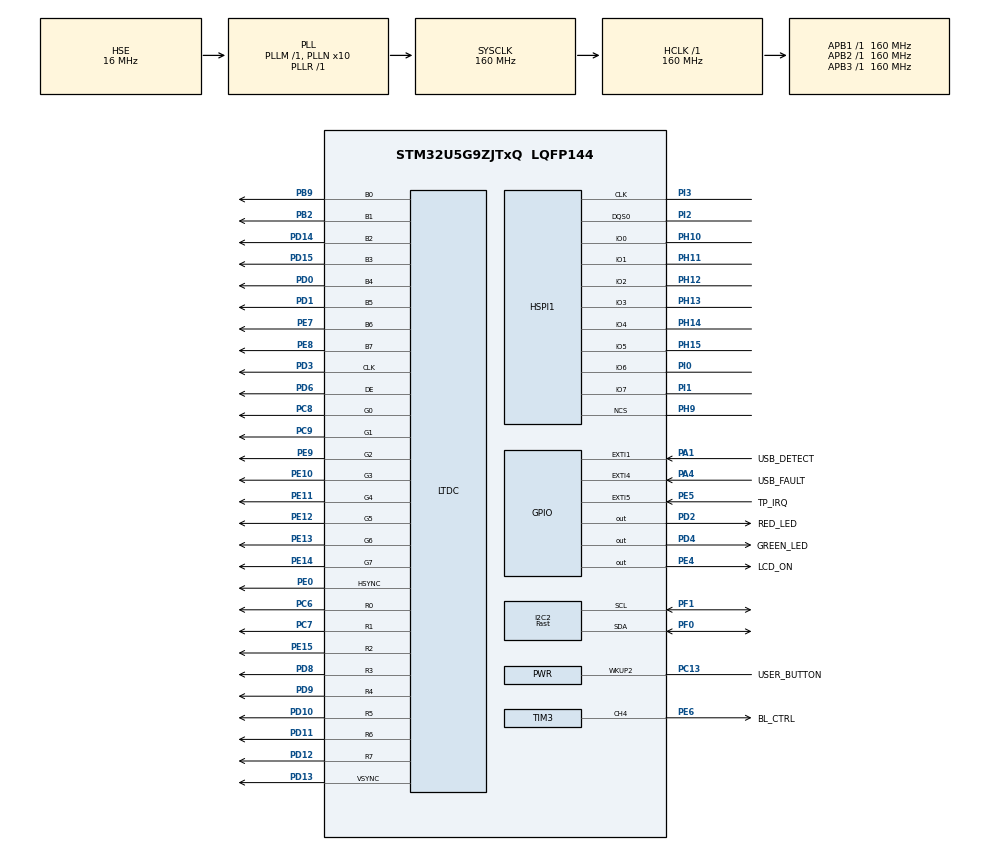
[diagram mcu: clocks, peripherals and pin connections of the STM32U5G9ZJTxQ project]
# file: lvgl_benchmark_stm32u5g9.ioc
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CORTEX_M33_NS.userName=CORTEX_M33
DMA2D.ColorMode=DMA2D_OUTPUT_RGB565
DMA2D.Mode=DMA2D_M2M
GPDMA1.RECAP_GPDMACH0=GPDMA1_REQUEST_JPEG_RX
GPDMA1.RECAP_GPDMACH1=GPDMA1_REQUEST_JPEG_TX
HSPI1.ChipSelectBoundary=HAL_XSPI_BONDARYOF_NONE
HSPI1.ChipSelectHighTimeCycle=2
HSPI1.FifoThresholdByte=4
HSPI1.MemorySize=HAL_XSPI_SIZE_1GB
HSPI1.MemoryType=HAL_XSPI_MEMTYPE_MACRONIX
I2C2.I2C_Speed_Mode=I2C_Fast
I2C2.Timing=0x00F07BFF
JPEG.JPEG_RGB_FORMAT=JPEG_RGB888
LTDC.ActiveH=480
LTDC.ActiveW=800
LTDC.Alpha_L0=255
LTDC.BlendingFactor1_L0=LTDC_BLENDING_FACTOR1_CA
LTDC.BlendingFactor2_L0=LTDC_BLENDING_FACTOR2_CA
LTDC.DEPolarity=LTDC_DEPOLARITY_AL
LTDC.FBStartAdress_L0=0x20000000
LTDC.HBP=8
LTDC.HFP=8
LTDC.HSync=5
LTDC.ImageHeight_L0=480
LTDC.ImageWidth_L0=800
LTDC.Layers=0
LTDC.PCPolarity=LTDC_PCPOLARITY_IPC
LTDC.PixelFormat_L0=LTDC_PIXEL_FORMAT_RGB565
LTDC.VBP=8
LTDC.VFP=14
LTDC.VSync=5
LTDC.WindowX1_L0=800
LTDC.WindowY1_L0=480
Mcu.Family=STM32U5
Mcu.Name=STM32U5G9ZJTxQ
Mcu.Package=LQFP144
NVIC.DMA2D_IRQn=true\:0\:0\:false\:false\:true\:true\:true\:true
NVIC.EXTI1_IRQn=true\:0\:0\:false\:false\:true\:true\:true\:true
NVIC.EXTI4_IRQn=true\:0\:0\:false\:false\:true\:true\:true\:true
NVIC.EXTI5_IRQn=true\:0\:0\:false\:false\:true\:true\:true\:true
NVIC.GPU2D_IRQn=true\:0\:0\:false\:false\:true\:true\:true\:true
NVIC.LTDC_IRQn=true\:0\:0\:false\:false\:true\:true\:true\:true
NVIC.PriorityGroup=NVIC_PRIORITYGROUP_4
PA1.GPIO_Label=USB_DETECT
PA1.GPIO_ModeDefaultEXTI=GPIO_MODE_IT_RISING_FALLING
PA1.Signal=GPXTI1
PA10.Signal=USART1_RX
PA11.Signal=USB_OTG_HS_DM
PA12.Signal=USB_OTG_HS_DP
PA13\ (JTMS/SWDIO).Mode=Trace_Asynchronous_SW
PA13\ (JTMS/SWDIO).Signal=DEBUG_JTMS-SWDIO
PA14\ (JTCK/SWCLK).Mode=Trace_Asynchronous_SW
PA14\ (JTCK/SWCLK).Signal=DEBUG_JTCK-SWCLK
PA4.GPIO_Label=USB_FAULT
PA4.GPIO_ModeDefaultEXTI=GPIO_MODE_IT_FALLING
PA4.GPIO_PuPd=GPIO_PULLUP
PA4.Signal=GPXTI4
PA9.Signal=USART1_TX
PB2.GPIO_Speed=GPIO_SPEED_FREQ_VERY_HIGH
PB2.Mode=RGB888
PB2.Signal=LTDC_B1
PB3\ (JTDO/TRACESWO).Mode=Trace_Asynchronous_SW
PB3\ (JTDO/TRACESWO).Signal=DEBUG_JTDO-SWO
PB9.GPIO_Speed=GPIO_SPEED_FREQ_VERY_HIGH
PB9.Mode=RGB888
PB9.Signal=LTDC_B0
PC13.GPIO_Label=USER_BUTTON
PC13.Mode=WakeUp2
PC13.Signal=PWR_WKUP2
PC14-OSC32_IN\ (PC14).Mode=LSE-External-Oscillator
PC14-OSC32_IN\ (PC14).Signal=RCC_OSC32_IN
PC15-OSC32_OUT\ (PC15).Mode=LSE-External-Oscillator
PC15-OSC32_OUT\ (PC15).Signal=RCC_OSC32_OUT
PC6.GPIO_Speed=GPIO_SPEED_FREQ_VERY_HIGH
PC6.Mode=RGB888
PC6.Signal=LTDC_R0
PC7.GPIO_Speed=GPIO_SPEED_FREQ_VERY_HIGH
PC7.Mode=RGB888
PC7.Signal=LTDC_R1
PC8.GPIO_Speed=GPIO_SPEED_FREQ_VERY_HIGH
PC8.Mode=RGB888
PC8.Signal=LTDC_G0
PC9.GPIO_Speed=GPIO_SPEED_FREQ_VERY_HIGH
PC9.Mode=RGB888
PC9.Signal=LTDC_G1
PD0.GPIO_Speed=GPIO_SPEED_FREQ_VERY_HIGH
PD0.Mode=RGB888
PD0.Signal=LTDC_B4
PD1.GPIO_Speed=GPIO_SPEED_FREQ_VERY_HIGH
PD1.Mode=RGB888
PD1.Signal=LTDC_B5
PD10.GPIO_Speed=GPIO_SPEED_FREQ_VERY_HIGH
PD10.Mode=RGB888
PD10.Signal=LTDC_R5
PD11.GPIO_Speed=GPIO_SPEED_FREQ_VERY_HIGH
PD11.Mode=RGB888
PD11.Signal=LTDC_R6
PD12.GPIO_Speed=GPIO_SPEED_FREQ_VERY_HIGH
PD12.Mode=RGB888
PD12.Signal=LTDC_R7
PD13.GPIO_Speed=GPIO_SPEED_FREQ_VERY_HIGH
PD13.Mode=RGB888
PD13.Signal=LTDC_VSYNC
PD14.GPIO_Speed=GPIO_SPEED_FREQ_VERY_HIGH
PD14.Mode=RGB888
PD14.Signal=LTDC_B2
PD15.GPIO_Speed=GPIO_SPEED_FREQ_VERY_HIGH
PD15.Mode=RGB888
PD15.Signal=LTDC_B3
PD2.GPIO_Label=RED_LED
PD2.Signal=GPIO_Output
PD3.GPIO_Speed=GPIO_SPEED_FREQ_VERY_HIGH
PD3.Mode=RGB888
PD3.Signal=LTDC_CLK
PD4.GPIO_Label=GREEN_LED
PD4.Signal=GPIO_Output
PD6.GPIO_Speed=GPIO_SPEED_FREQ_VERY_HIGH
PD6.Mode=RGB888
PD6.Signal=LTDC_DE
PD8.GPIO_Speed=GPIO_SPEED_FREQ_VERY_HIGH
PD8.Mode=RGB888
PD8.Signal=LTDC_R3
PD9.GPIO_Speed=GPIO_SPEED_FREQ_VERY_HIGH
PD9.Mode=RGB888
PD9.Signal=LTDC_R4
PE0.GPIO_Speed=GPIO_SPEED_FREQ_VERY_HIGH
PE0.Mode=RGB888
PE0.Signal=LTDC_HSYNC
PE10.GPIO_Speed=GPIO_SPEED_FREQ_VERY_HIGH
PE10.Mode=RGB888
PE10.Signal=LTDC_G3
PE11.GPIO_Speed=GPIO_SPEED_FREQ_VERY_HIGH
PE11.Mode=RGB888
PE11.Signal=LTDC_G4
PE12.GPIO_Speed=GPIO_SPEED_FREQ_VERY_HIGH
PE12.Mode=RGB888
PE12.Signal=LTDC_G5
PE13.GPIO_Speed=GPIO_SPEED_FREQ_VERY_HIGH
PE13.Mode=RGB888
PE13.Signal=LTDC_G6
PE14.GPIO_Speed=GPIO_SPEED_FREQ_VERY_HIGH
PE14.Mode=RGB888
PE14.Signal=LTDC_G7
PE15.GPIO_Speed=GPIO_SPEED_FREQ_VERY_HIGH
PE15.Mode=RGB888
PE15.Signal=LTDC_R2
PE4.GPIO_Label=LCD_ON
PE4.PinState=GPIO_PIN_SET
PE4.Signal=GPIO_Output
PE5.GPIO_Label=TP_IRQ
PE5.GPIO_ModeDefaultEXTI=GPIO_MODE_IT_FALLING
PE5.GPIO_PuPd=GPIO_PULLUP
PE5.Signal=GPXTI5
PE6.GPIO_Label=BL_CTRL
PE6.Signal=S_TIM3_CH4
PE7.GPIO_Speed=GPIO_SPEED_FREQ_VERY_HIGH
PE7.Mode=RGB888
PE7.Signal=LTDC_B6
PE8.GPIO_Speed=GPIO_SPEED_FREQ_VERY_HIGH
PE8.Mode=RGB888
PE8.Signal=LTDC_B7
PE9.GPIO_Speed=GPIO_SPEED_FREQ_VERY_HIGH
PE9.Mode=RGB888
PE9.Signal=LTDC_G2
PF0.Mode=I2C
PF0.Signal=I2C2_SDA
PF1.Mode=I2C
PF1.Signal=I2C2_SCL
PH0-OSC_IN\ (PH0).Mode=HSE-External-Oscillator
PH0-OSC_IN\ (PH0).Signal=RCC_OSC_IN
PH1-OSC_OUT\ (PH1).Mode=HSE-External-Oscillator
PH1-OSC_OUT\ (PH1).Signal=RCC_OSC_OUT
PH10.Mode=octo_mode
PH10.Signal=HSPI1_IO0
PH11.Mode=octo_mode
PH11.Signal=HSPI1_IO1
PH12.Mode=octo_mode
PH12.Signal=HSPI1_IO2
PH13.Mode=octo_mode
PH13.Signal=HSPI1_IO3
PH14.Mode=octo_mode
PH14.Signal=HSPI1_IO4
PH15.Mode=octo_mode
PH15.Signal=HSPI1_IO5
PH9.Mode=octo_mode
PH9.Signal=HSPI1_NCS
PI0.Mode=octo_mode
PI0.Signal=HSPI1_IO6
PI1.Mode=octo_mode
PI1.Signal=HSPI1_IO7
PI2.Mode=octo_mode
PI2.Signal=HSPI1_DQS0
PI3.Mode=octo_mode
PI3.Signal=HSPI1_CLK
PWR.PowerMode=PWR_SMPS_SUPPLY
ProjectManager.HeapSize=0x200
ProjectManager.StackSize=0x400
ProjectManager.TargetToolchain=STM32CubeIDE
RCC.ADCFreq_Value=16000000
RCC.AHBFreq_Value=160000000
RCC.APB1Freq_Value=160000000
RCC.APB1TimFreq_Value=160000000
RCC.APB2Freq_Value=160000000
RCC.APB2TimFreq_Value=160000000
RCC.APB3Freq_Value=160000000
RCC.CortexFreq_Value=160000000
RCC.EPOD_VALUE=16000000
RCC.HCLKFreq_Value=160000000
RCC.HSE_VALUE=16000000
RCC.HSI48_VALUE=48000000
RCC.HSI_VALUE=16000000
RCC.HSPICLockSelection=RCC_HSPICLKSOURCE_PLL2
RCC.LSIDIV_VALUE=32000
RCC.LTDCCLockSelection=RCC_LTDCCLKSOURCE_PLL3
RCC.MSIClockRange=RCC_MSIRANGE_0
RCC.MSI_VALUE=48000000
RCC.PLL1P=8
RCC.PLL1R=1
RCC.PLL2FRACN=0
RCC.PLL2N=25
RCC.PLL2Q=3
RCC.PLL2R=4
RCC.PLL2Source=RCC_PLLSOURCE_HSE
RCC.PLL3FRACN=0
RCC.PLL3M=4
RCC.PLL3N=50
RCC.PLL3R=8
RCC.PLL3Source=RCC_PLLSOURCE_HSE
RCC.PLLFRACN=0
RCC.PLLN=10
RCC.PLLSourceVirtual=RCC_PLLSOURCE_HSE
RCC.RTCClockSelection=RCC_RTCCLKSOURCE_LSE
RCC.SYSCLKFreq_VALUE=160000000
RCC.SYSCLKSource=RCC_SYSCLKSOURCE_PLLCLK
RCC.VCOOutputFreq_Value=160000000
SH.S_TIM3_CH4.0=TIM3_CH4,PWM Generation4 CH4
STMicroelectronics.X-CUBE-FREERTOS.1.3.1.configENABLE_FPU=1
STMicroelectronics.X-CUBE-FREERTOS.1.3.1.configENABLE_MVE=0
STMicroelectronics.X-CUBE-FREERTOS.1.3.1.configMINIMAL_STACK_SIZE=4096
STMicroelectronics.X-CUBE-FREERTOS.1.3.1.configTOTAL_HEAP_SIZE=1024*256
STMicroelectronics.X-CUBE-FREERTOS.1.3.1.configUSE_TICK_HOOK=1
TIM3.Channel-PWM\ Generation4\ CH4=TIM_CHANNEL_4
TIM3.OC4Preload_PWM=DISABLE
TIM3.PeriodNoDither=100
TIM3.Prescaler=160
TIM3.PulseNoDither_4=75
VP_DCACHE1_VS_DCACHE.Mode=DCACHE_Activate
VP_DCACHE2_VS_DCACHE.Mode=DCACHE_Activate
VP_DMA2D_VS_DMA2D.Mode=DMA2D_Activate
VP_GPDMA1_VS_GPDMACH0.Mode=SIMPLEREQUEST_GPDMACH0
VP_GPDMA1_VS_GPDMACH1.Mode=SIMPLEREQUEST_GPDMACH1
VP_GPU2D_VS_GPU2D.Mode=GPU2D_Activate
VP_ICACHE_VS_ICACHE.Mode=DirectMappedCache
VP_JPEG_VS_JPEG.Mode=JPEG_Activate
VP_LPBAMQUEUE_VS_QUEUE.Mode=QUEUEMODE
VP_LPBAM_VS_SIG1.Mode=SmartRun
VP_LPBAM_VS_SIG4.Mode=LPDMA1
VP_MEMORYMAP_VS_MEMORYMAP.Mode=CurAppReg
VP_PWR_VS_LPOM.Mode=PowerOptimisation
VP_PWR_VS_SECSignals.Mode=Security/Privilege
board=STM32U5G9J-DK2

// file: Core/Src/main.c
/* USER CODE BEGIN Header */
/**
  ******************************************************************************
  * @file           : main.c
  * @brief          : Main program body
  ******************************************************************************
  * @attention
  *
  * Copyright (c) 2026 STMicroelectronics.
  * All rights reserved.
  *
  * This software is licensed under terms that can be found in the LICENSE file
  * in the root directory of this software component.
  * If no LICENSE file comes with this software, it is provided AS-IS.
  *
  ******************************************************************************
  */
/* USER CODE END Header */
#include "main.h"
#include "jpeg_utils_conf.h"

/* USER CODE BEGIN Includes */
#include "lvgl_port_display.h"
#include "lvgl.h"
//#include "../lvgl/examples/lv_examples.h"
#include "examples/lv_examples.h"
#include "demos/lv_demos.h"
//#include "app_freertos.h"
/* USER CODE END Includes */

DCACHE_HandleTypeDef hdcache1;
DCACHE_HandleTypeDef hdcache2;

DMA2D_HandleTypeDef hdma2d;

DMA_HandleTypeDef handle_GPDMA1_Channel1;
DMA_HandleTypeDef handle_GPDMA1_Channel0;

GPU2D_HandleTypeDef hgpu2d;

XSPI_HandleTypeDef hxspi1;

I2C_HandleTypeDef hi2c2;

JPEG_HandleTypeDef hjpeg;

LTDC_HandleTypeDef hltdc;

TIM_HandleTypeDef htim3;

/* USER CODE BEGIN PV */

//volatile __attribute__((aligned(16))) uint8_t ltdc_framebuffer[800 * 480 * 2]; //FIXME A remettre si on veut que ca fonctionne
/* USER CODE END PV */

void SystemClock_Config(void);
static void SystemPower_Config(void);
static void MX_GPIO_Init(void);
static void MX_GPDMA1_Init(void);
static void MX_DMA2D_Init(void);
static void MX_HSPI1_Init(void);
static void MX_I2C2_Init(void);
static void MX_ICACHE_Init(void);
static void MX_LTDC_Init(void);
static void MX_TIM3_Init(void);
static void MX_JPEG_Init(void);
static void MX_DCACHE1_Init(void);
static void MX_GPU2D_Init(void);
static void MX_DCACHE2_Init(void);

int main(void)
{

  /* MCU Configuration--------------------------------------------------------*/

  /* Reset of all peripherals, Initializes the Flash interface and the Systick. */
  HAL_Init();

  /* Configure the System Power */
  SystemPower_Config();

  /* Configure the system clock */
  SystemClock_Config();

  /* Initialize all configured peripherals */
  MX_GPIO_Init();
  MX_GPDMA1_Init();
  MX_DMA2D_Init();
  MX_HSPI1_Init();
  MX_I2C2_Init();
  MX_ICACHE_Init();
  MX_LTDC_Init();
  MX_TIM3_Init();
  MX_JPEG_Init();
  MX_DCACHE1_Init();
  MX_GPU2D_Init();
  MX_DCACHE2_Init();
  /* USER CODE BEGIN 2 */
lv_init();
lvgl_display_init ();
//lv_demo_music();
//lv_demo_benchmark();
//lv_example_svg_1();
lv_example_label_1();
  /* USER CODE END 2 */

  /* Infinite loop */
  /* USER CODE BEGIN WHILE */
  while (1)
  {
	    lv_timer_handler();
	    HAL_Delay(1);
    /* USER CODE END WHILE */

  }
}

void SystemClock_Config(void)
{
  RCC_OscInitTypeDef RCC_OscInitStruct = {0};
  RCC_ClkInitTypeDef RCC_ClkInitStruct = {0};

  /** Configure the main internal regulator output voltage
  */
  if (HAL_PWREx_ControlVoltageScaling(PWR_REGULATOR_VOLTAGE_SCALE1) != HAL_OK)
  {
    Error_Handler();
  }

  /** Initializes the CPU, AHB and APB buses clocks
  */
  RCC_OscInitStruct.OscillatorType = RCC_OSCILLATORTYPE_HSE;
  RCC_OscInitStruct.HSEState = RCC_HSE_ON;
  RCC_OscInitStruct.PLL.PLLState = RCC_PLL_ON;
  RCC_OscInitStruct.PLL.PLLSource = RCC_PLLSOURCE_HSE;
  RCC_OscInitStruct.PLL.PLLMBOOST = RCC_PLLMBOOST_DIV1;
  RCC_OscInitStruct.PLL.PLLM = 1;
  RCC_OscInitStruct.PLL.PLLN = 10;
  RCC_OscInitStruct.PLL.PLLP = 8;
  RCC_OscInitStruct.PLL.PLLQ = 2;
  RCC_OscInitStruct.PLL.PLLR = 1;
  RCC_OscInitStruct.PLL.PLLRGE = RCC_PLLVCIRANGE_1;
  RCC_OscInitStruct.PLL.PLLFRACN = 0;
  if (HAL_RCC_OscConfig(&RCC_OscInitStruct) != HAL_OK)
  {
    Error_Handler();
  }

  /** Initializes the CPU, AHB and APB buses clocks
  */
  RCC_ClkInitStruct.ClockType = RCC_CLOCKTYPE_HCLK|RCC_CLOCKTYPE_SYSCLK
                              |RCC_CLOCKTYPE_PCLK1|RCC_CLOCKTYPE_PCLK2
                              |RCC_CLOCKTYPE_PCLK3;
  RCC_ClkInitStruct.SYSCLKSource = RCC_SYSCLKSOURCE_PLLCLK;
  RCC_ClkInitStruct.AHBCLKDivider = RCC_SYSCLK_DIV1;
  RCC_ClkInitStruct.APB1CLKDivider = RCC_HCLK_DIV1;
  RCC_ClkInitStruct.APB2CLKDivider = RCC_HCLK_DIV1;
  RCC_ClkInitStruct.APB3CLKDivider = RCC_HCLK_DIV1;

  if (HAL_RCC_ClockConfig(&RCC_ClkInitStruct, FLASH_LATENCY_4) != HAL_OK)
  {
    Error_Handler();
  }
}

/**
  * @brief Power Configuration
  * @retval None
  */
static void SystemPower_Config(void)
{

  /*
   * Switch to SMPS regulator instead of LDO
   */
  if (HAL_PWREx_ConfigSupply(PWR_SMPS_SUPPLY) != HAL_OK)
  {
    Error_Handler();
  }
}

static void MX_DCACHE1_Init(void)
{

  hdcache1.Instance = DCACHE1;
  hdcache1.Init.ReadBurstType = DCACHE_READ_BURST_WRAP;
  if (HAL_DCACHE_Init(&hdcache1) != HAL_OK)
  {
    Error_Handler();
  }

}

static void MX_DCACHE2_Init(void)
{

  hdcache2.Instance = DCACHE2;
  hdcache2.Init.ReadBurstType = DCACHE_READ_BURST_WRAP;
  if (HAL_DCACHE_Init(&hdcache2) != HAL_OK)
  {
    Error_Handler();
  }
   __HAL_RCC_SYSCFG_CLK_ENABLE();
   HAL_SYSCFG_DisableSRAMCached();

}

static void MX_DMA2D_Init(void)
{

  hdma2d.Instance = DMA2D;
  hdma2d.Init.Mode = DMA2D_M2M;
  hdma2d.Init.ColorMode = DMA2D_OUTPUT_RGB565;
  hdma2d.Init.OutputOffset = 0;
  hdma2d.Init.BytesSwap = DMA2D_BYTES_REGULAR;
  hdma2d.Init.LineOffsetMode = DMA2D_LOM_PIXELS;
  hdma2d.LayerCfg[1].InputOffset = 0;
  hdma2d.LayerCfg[1].InputColorMode = DMA2D_INPUT_RGB565;
  hdma2d.LayerCfg[1].AlphaMode = DMA2D_NO_MODIF_ALPHA;
  hdma2d.LayerCfg[1].InputAlpha = 0;
  hdma2d.LayerCfg[1].AlphaInverted = DMA2D_REGULAR_ALPHA;
  hdma2d.LayerCfg[1].RedBlueSwap = DMA2D_RB_REGULAR;
  if (HAL_DMA2D_Init(&hdma2d) != HAL_OK)
  {
    Error_Handler();
  }
  if (HAL_DMA2D_ConfigLayer(&hdma2d, 1) != HAL_OK)
  {
    Error_Handler();
  }

}

static void MX_GPDMA1_Init(void)
{

  /* Peripheral clock enable */
  __HAL_RCC_GPDMA1_CLK_ENABLE();

  handle_GPDMA1_Channel1.Instance = GPDMA1_Channel1;
  handle_GPDMA1_Channel1.Init.Request = DMA_REQUEST_SW;
  handle_GPDMA1_Channel1.Init.BlkHWRequest = DMA_BREQ_SINGLE_BURST;
  handle_GPDMA1_Channel1.Init.Direction = DMA_MEMORY_TO_MEMORY;
  handle_GPDMA1_Channel1.Init.SrcInc = DMA_SINC_FIXED;
  handle_GPDMA1_Channel1.Init.DestInc = DMA_DINC_FIXED;
  handle_GPDMA1_Channel1.Init.SrcDataWidth = DMA_SRC_DATAWIDTH_BYTE;
  handle_GPDMA1_Channel1.Init.DestDataWidth = DMA_DEST_DATAWIDTH_BYTE;
  handle_GPDMA1_Channel1.Init.Priority = DMA_LOW_PRIORITY_LOW_WEIGHT;
  handle_GPDMA1_Channel1.Init.SrcBurstLength = 1;
  handle_GPDMA1_Channel1.Init.DestBurstLength = 1;
  handle_GPDMA1_Channel1.Init.TransferAllocatedPort = DMA_SRC_ALLOCATED_PORT0|DMA_DEST_ALLOCATED_PORT0;
  handle_GPDMA1_Channel1.Init.TransferEventMode = DMA_TCEM_BLOCK_TRANSFER;
  handle_GPDMA1_Channel1.Init.Mode = DMA_NORMAL;
  if (HAL_DMA_Init(&handle_GPDMA1_Channel1) != HAL_OK)
  {
    Error_Handler();
  }
  if (HAL_DMA_ConfigChannelAttributes(&handle_GPDMA1_Channel1, DMA_CHANNEL_NPRIV) != HAL_OK)
  {
    Error_Handler();
  }
  handle_GPDMA1_Channel0.Instance = GPDMA1_Channel0;
  handle_GPDMA1_Channel0.Init.Request = DMA_REQUEST_SW;
  handle_GPDMA1_Channel0.Init.BlkHWRequest = DMA_BREQ_SINGLE_BURST;
  handle_GPDMA1_Channel0.Init.Direction = DMA_MEMORY_TO_MEMORY;
  handle_GPDMA1_Channel0.Init.SrcInc = DMA_SINC_FIXED;
  handle_GPDMA1_Channel0.Init.DestInc = DMA_DINC_FIXED;
  handle_GPDMA1_Channel0.Init.SrcDataWidth = DMA_SRC_DATAWIDTH_BYTE;
  handle_GPDMA1_Channel0.Init.DestDataWidth = DMA_DEST_DATAWIDTH_BYTE;
  handle_GPDMA1_Channel0.Init.Priority = DMA_LOW_PRIORITY_LOW_WEIGHT;
  handle_GPDMA1_Channel0.Init.SrcBurstLength = 1;
  handle_GPDMA1_Channel0.Init.DestBurstLength = 1;
  handle_GPDMA1_Channel0.Init.TransferAllocatedPort = DMA_SRC_ALLOCATED_PORT0|DMA_DEST_ALLOCATED_PORT0;
  handle_GPDMA1_Channel0.Init.TransferEventMode = DMA_TCEM_BLOCK_TRANSFER;
  handle_GPDMA1_Channel0.Init.Mode = DMA_NORMAL;
  if (HAL_DMA_Init(&handle_GPDMA1_Channel0) != HAL_OK)
  {
    Error_Handler();
  }
  if (HAL_DMA_ConfigChannelAttributes(&handle_GPDMA1_Channel0, DMA_CHANNEL_NPRIV) != HAL_OK)
  {
    Error_Handler();
  }

}

static void MX_GPU2D_Init(void)
{

  hgpu2d.Instance = GPU2D;
  if (HAL_GPU2D_Init(&hgpu2d) != HAL_OK)
  {
    Error_Handler();
  }

}

static void MX_HSPI1_Init(void)
{

  /* HSPI1 parameter configuration*/
  hxspi1.Instance = HSPI1;
  hxspi1.Init.FifoThresholdByte = 4;
  hxspi1.Init.MemoryMode = HAL_XSPI_SINGLE_MEM;
  hxspi1.Init.MemoryType = HAL_XSPI_MEMTYPE_MACRONIX;
  hxspi1.Init.MemorySize = HAL_XSPI_SIZE_1GB;
  hxspi1.Init.ChipSelectHighTimeCycle = 2;
  hxspi1.Init.FreeRunningClock = HAL_XSPI_FREERUNCLK_DISABLE;
  hxspi1.Init.ClockMode = HAL_XSPI_CLOCK_MODE_0;
  hxspi1.Init.WrapSize = HAL_XSPI_WRAP_NOT_SUPPORTED;
  hxspi1.Init.ClockPrescaler = 0;
  hxspi1.Init.SampleShifting = HAL_XSPI_SAMPLE_SHIFT_NONE;
  hxspi1.Init.DelayHoldQuarterCycle = HAL_XSPI_DHQC_DISABLE;
  hxspi1.Init.ChipSelectBoundary = HAL_XSPI_BONDARYOF_NONE;
  hxspi1.Init.MaxTran = 0;
  hxspi1.Init.Refresh = 0;
  if (HAL_XSPI_Init(&hxspi1) != HAL_OK)
  {
    Error_Handler();
  }

}

static void MX_I2C2_Init(void)
{

  hi2c2.Instance = I2C2;
  hi2c2.Init.Timing = 0x00F07BFF;
  hi2c2.Init.OwnAddress1 = 0;
  hi2c2.Init.AddressingMode = I2C_ADDRESSINGMODE_7BIT;
  hi2c2.Init.DualAddressMode = I2C_DUALADDRESS_DISABLE;
  hi2c2.Init.OwnAddress2 = 0;
  hi2c2.Init.OwnAddress2Masks = I2C_OA2_NOMASK;
  hi2c2.Init.GeneralCallMode = I2C_GENERALCALL_DISABLE;
  hi2c2.Init.NoStretchMode = I2C_NOSTRETCH_DISABLE;
  if (HAL_I2C_Init(&hi2c2) != HAL_OK)
  {
    Error_Handler();
  }

  /** Configure Analogue filter
  */
  if (HAL_I2CEx_ConfigAnalogFilter(&hi2c2, I2C_ANALOGFILTER_ENABLE) != HAL_OK)
  {
    Error_Handler();
  }

  /** Configure Digital filter
  */
  if (HAL_I2CEx_ConfigDigitalFilter(&hi2c2, 0) != HAL_OK)
  {
    Error_Handler();
  }

}

static void MX_ICACHE_Init(void)
{

  /** Enable instruction cache in 1-way (direct mapped cache)
  */
  if (HAL_ICACHE_ConfigAssociativityMode(ICACHE_1WAY) != HAL_OK)
  {
    Error_Handler();
  }
  if (HAL_ICACHE_Enable() != HAL_OK)
  {
    Error_Handler();
  }

}

static void MX_JPEG_Init(void)
{

  hjpeg.Instance = JPEG;
  if (HAL_JPEG_Init(&hjpeg) != HAL_OK)
  {
    Error_Handler();
  }

}

static void MX_LTDC_Init(void)
{

  LTDC_LayerCfgTypeDef pLayerCfg = {0};

  hltdc.Instance = LTDC;
  hltdc.Init.HSPolarity = LTDC_HSPOLARITY_AL;
  hltdc.Init.VSPolarity = LTDC_VSPOLARITY_AL;
  hltdc.Init.DEPolarity = LTDC_DEPOLARITY_AL;
  hltdc.Init.PCPolarity = LTDC_PCPOLARITY_IPC;
  hltdc.Init.HorizontalSync = 4;
  hltdc.Init.VerticalSync = 4;
  hltdc.Init.AccumulatedHBP = 12;
  hltdc.Init.AccumulatedVBP = 12;
  hltdc.Init.AccumulatedActiveW = 812;
  hltdc.Init.AccumulatedActiveH = 492;
  hltdc.Init.TotalWidth = 820;
  hltdc.Init.TotalHeigh = 506;
  hltdc.Init.Backcolor.Blue = 0;
  hltdc.Init.Backcolor.Green = 0;
  hltdc.Init.Backcolor.Red = 0;
  if (HAL_LTDC_Init(&hltdc) != HAL_OK)
  {
    Error_Handler();
  }
  pLayerCfg.WindowX0 = 0;
  pLayerCfg.WindowX1 = 800;
  pLayerCfg.WindowY0 = 0;
  pLayerCfg.WindowY1 = 480;
  pLayerCfg.PixelFormat = LTDC_PIXEL_FORMAT_RGB565;
  pLayerCfg.Alpha = 255;
  pLayerCfg.Alpha0 = 0;
  pLayerCfg.BlendingFactor1 = LTDC_BLENDING_FACTOR1_CA;
  pLayerCfg.BlendingFactor2 = LTDC_BLENDING_FACTOR2_CA;
  pLayerCfg.FBStartAdress = 0x20000000;
  pLayerCfg.ImageWidth = 800;
  pLayerCfg.ImageHeight = 480;
  pLayerCfg.Backcolor.Blue = 0;
  pLayerCfg.Backcolor.Green = 0;
  pLayerCfg.Backcolor.Red = 0;
  if (HAL_LTDC_ConfigLayer(&hltdc, &pLayerCfg, 0) != HAL_OK)
  {
    Error_Handler();
  }
  /* USER CODE BEGIN LTDC_Init 2 */
  //FIXME A remettre si on veut que ca fonctionne
//  pLayerCfg.FBStartAdress = (uint32_t)ltdc_framebuffer;
//  if (HAL_LTDC_ConfigLayer(&hltdc, &pLayerCfg, 0) != HAL_OK)
//  {
//    Error_Handler();
//  }
  /* USER CODE END LTDC_Init 2 */

}

static void MX_TIM3_Init(void)
{

  TIM_MasterConfigTypeDef sMasterConfig = {0};
  TIM_OC_InitTypeDef sConfigOC = {0};

  htim3.Instance = TIM3;
  htim3.Init.Prescaler = 160;
  htim3.Init.CounterMode = TIM_COUNTERMODE_UP;
  htim3.Init.Period = 100;
  htim3.Init.ClockDivision = TIM_CLOCKDIVISION_DIV1;
  htim3.Init.AutoReloadPreload = TIM_AUTORELOAD_PRELOAD_DISABLE;
  if (HAL_TIM_PWM_Init(&htim3) != HAL_OK)
  {
    Error_Handler();
  }
  sMasterConfig.MasterOutputTrigger = TIM_TRGO_RESET;
  sMasterConfig.MasterSlaveMode = TIM_MASTERSLAVEMODE_DISABLE;
  if (HAL_TIMEx_MasterConfigSynchronization(&htim3, &sMasterConfig) != HAL_OK)
  {
    Error_Handler();
  }
  sConfigOC.OCMode = TIM_OCMODE_PWM1;
  sConfigOC.Pulse = 75;
  sConfigOC.OCPolarity = TIM_OCPOLARITY_HIGH;
  sConfigOC.OCFastMode = TIM_OCFAST_DISABLE;
  if (HAL_TIM_PWM_ConfigChannel(&htim3, &sConfigOC, TIM_CHANNEL_4) != HAL_OK)
  {
    Error_Handler();
  }
  __HAL_TIM_DISABLE_OCxPRELOAD(&htim3, TIM_CHANNEL_4);
  HAL_TIM_MspPostInit(&htim3);

}

static void MX_GPIO_Init(void)
{
  GPIO_InitTypeDef GPIO_InitStruct = {0};

  /* GPIO Ports Clock Enable */
  __HAL_RCC_GPIOE_CLK_ENABLE();
  __HAL_RCC_GPIOC_CLK_ENABLE();
  __HAL_RCC_GPIOF_CLK_ENABLE();
  __HAL_RCC_GPIOH_CLK_ENABLE();
  __HAL_RCC_GPIOA_CLK_ENABLE();
  __HAL_RCC_GPIOB_CLK_ENABLE();
  __HAL_RCC_GPIOD_CLK_ENABLE();
  __HAL_RCC_GPIOI_CLK_ENABLE();

  /*Configure GPIO pin Output Level */
  HAL_GPIO_WritePin(LCD_ON_GPIO_Port, LCD_ON_Pin, GPIO_PIN_SET);

  /*Configure GPIO pin Output Level */
  HAL_GPIO_WritePin(GPIOD, RED_LED_Pin|GREEN_LED_Pin, GPIO_PIN_RESET);

  /*Configure GPIO pin : LCD_ON_Pin */
  GPIO_InitStruct.Pin = LCD_ON_Pin;
  GPIO_InitStruct.Mode = GPIO_MODE_OUTPUT_PP;
  GPIO_InitStruct.Pull = GPIO_NOPULL;
  GPIO_InitStruct.Speed = GPIO_SPEED_FREQ_LOW;
  HAL_GPIO_Init(LCD_ON_GPIO_Port, &GPIO_InitStruct);

  /*Configure GPIO pin : TP_IRQ_Pin */
  GPIO_InitStruct.Pin = TP_IRQ_Pin;
  GPIO_InitStruct.Mode = GPIO_MODE_IT_FALLING;
  GPIO_InitStruct.Pull = GPIO_PULLUP;
  HAL_GPIO_Init(TP_IRQ_GPIO_Port, &GPIO_InitStruct);

  /*Configure GPIO pin : USB_DETECT_Pin */
  GPIO_InitStruct.Pin = USB_DETECT_Pin;
  GPIO_InitStruct.Mode = GPIO_MODE_IT_RISING_FALLING;
  GPIO_InitStruct.Pull = GPIO_NOPULL;
  HAL_GPIO_Init(USB_DETECT_GPIO_Port, &GPIO_InitStruct);

  /*Configure GPIO pin : USB_FAULT_Pin */
  GPIO_InitStruct.Pin = USB_FAULT_Pin;
  GPIO_InitStruct.Mode = GPIO_MODE_IT_FALLING;
  GPIO_InitStruct.Pull = GPIO_PULLUP;
  HAL_GPIO_Init(USB_FAULT_GPIO_Port, &GPIO_InitStruct);

  /*Configure GPIO pins : PA9 PA10 */
  GPIO_InitStruct.Pin = GPIO_PIN_9|GPIO_PIN_10;
  GPIO_InitStruct.Mode = GPIO_MODE_AF_PP;
  GPIO_InitStruct.Pull = GPIO_NOPULL;
  GPIO_InitStruct.Speed = GPIO_SPEED_FREQ_LOW;
  GPIO_InitStruct.Alternate = GPIO_AF7_USART1;
  HAL_GPIO_Init(GPIOA, &GPIO_InitStruct);

  /*Configure GPIO pins : PA11 PA12 */
  GPIO_InitStruct.Pin = GPIO_PIN_11|GPIO_PIN_12;
  GPIO_InitStruct.Mode = GPIO_MODE_AF_PP;
  GPIO_InitStruct.Pull = GPIO_NOPULL;
  GPIO_InitStruct.Speed = GPIO_SPEED_FREQ_LOW;
  HAL_GPIO_Init(GPIOA, &GPIO_InitStruct);

  /*Configure GPIO pins : RED_LED_Pin GREEN_LED_Pin */
  GPIO_InitStruct.Pin = RED_LED_Pin|GREEN_LED_Pin;
  GPIO_InitStruct.Mode = GPIO_MODE_OUTPUT_PP;
  GPIO_InitStruct.Pull = GPIO_NOPULL;
  GPIO_InitStruct.Speed = GPIO_SPEED_FREQ_LOW;
  HAL_GPIO_Init(GPIOD, &GPIO_InitStruct);

  /* EXTI interrupt init*/
  HAL_NVIC_SetPriority(EXTI1_IRQn, 0, 0);
  HAL_NVIC_EnableIRQ(EXTI1_IRQn);

  HAL_NVIC_SetPriority(EXTI4_IRQn, 0, 0);
  HAL_NVIC_EnableIRQ(EXTI4_IRQn);

  HAL_NVIC_SetPriority(EXTI5_IRQn, 0, 0);
  HAL_NVIC_EnableIRQ(EXTI5_IRQn);

}

void Error_Handler(void)
{
  __disable_irq();
  while (1)
  {
  }
}
